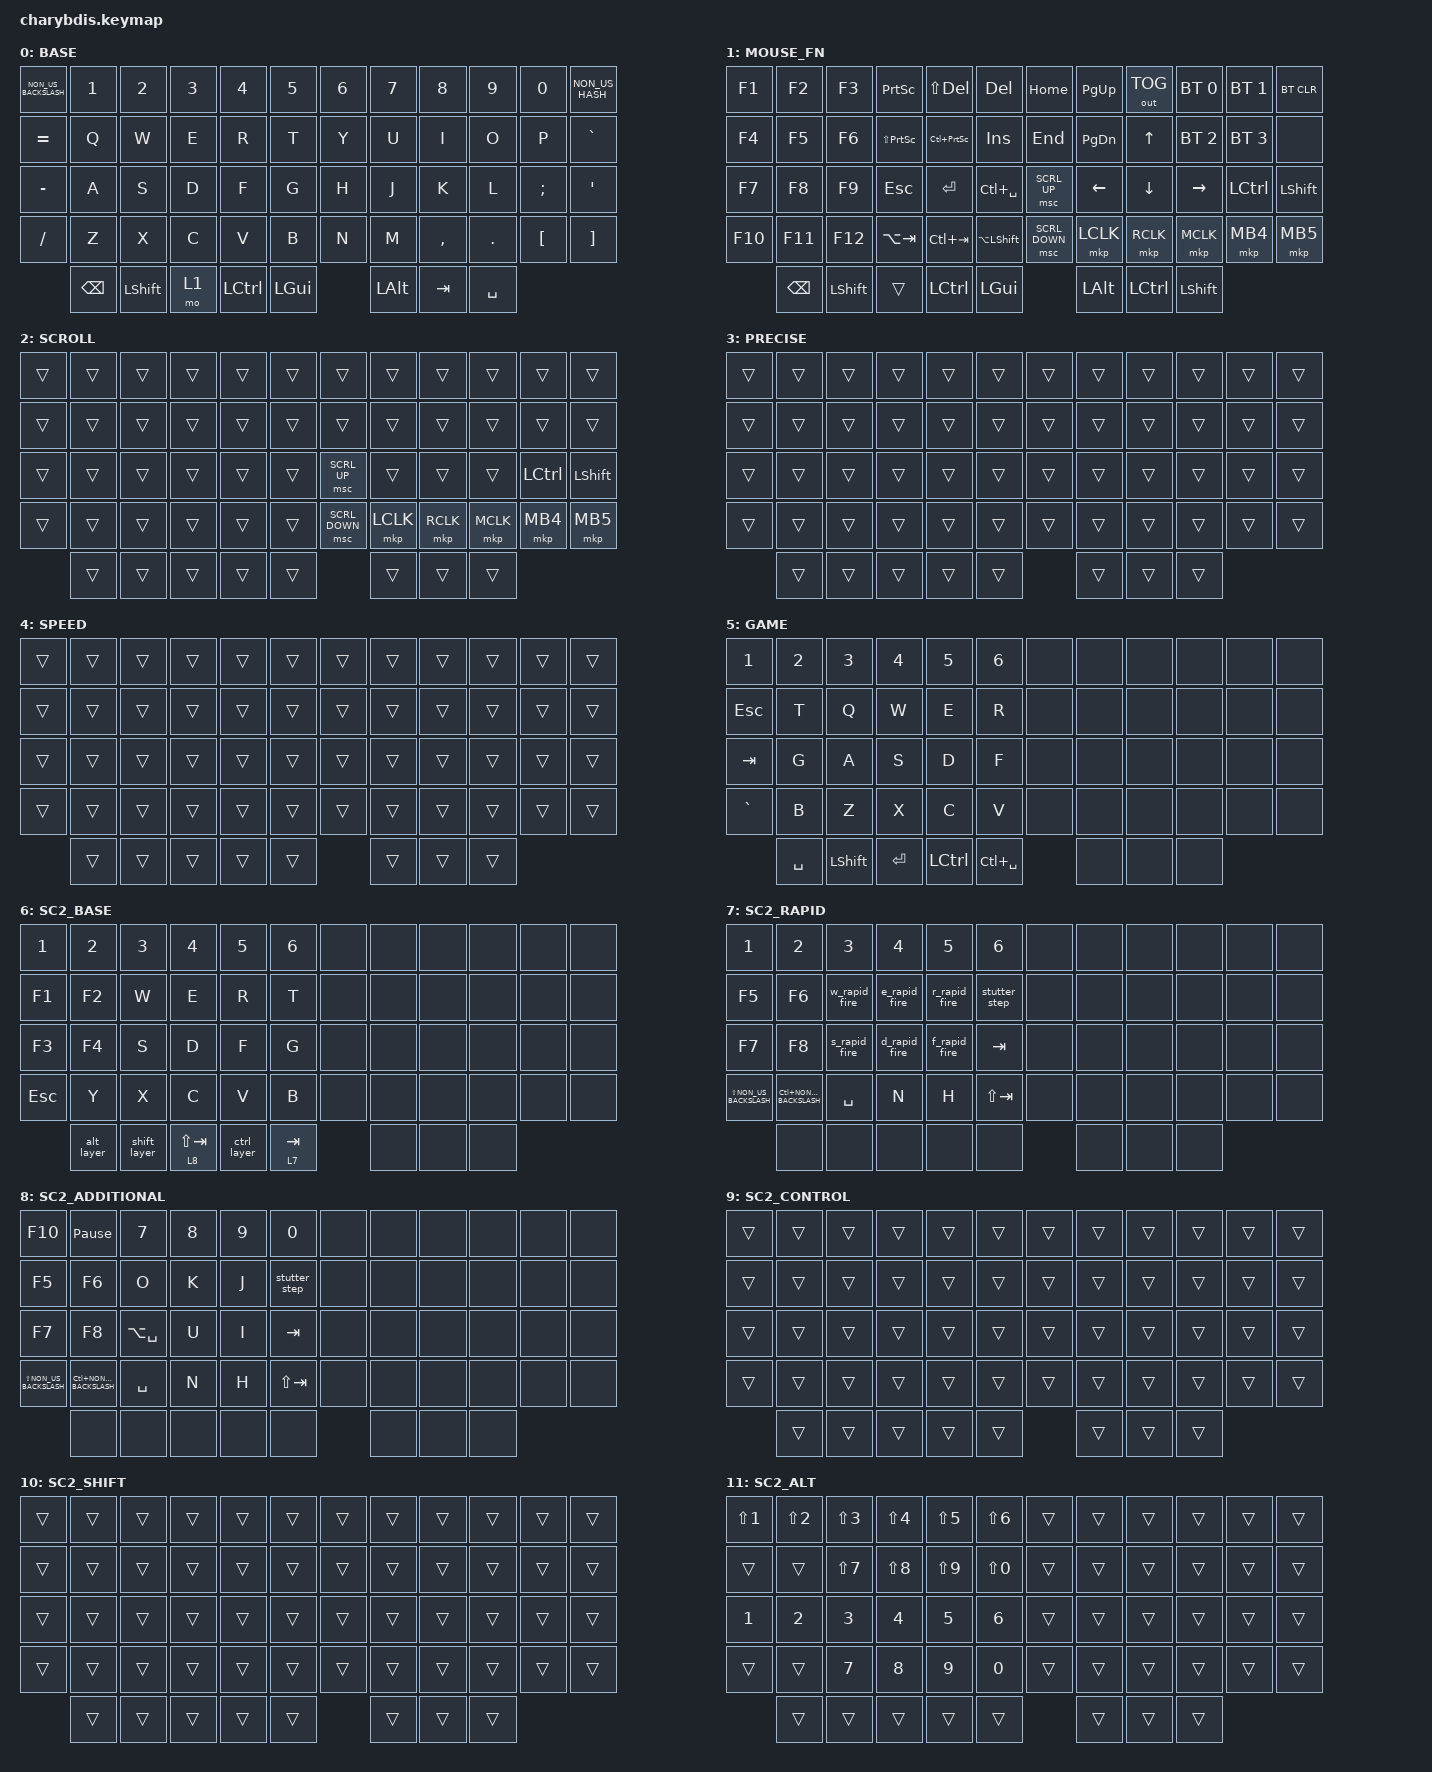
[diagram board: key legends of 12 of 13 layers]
#include <dt-bindings/zmk/mouse.h>
#include <behaviors/mouse_keys.dtsi>
#include <behaviors.dtsi>
#include <dt-bindings/zmk/bt.h>
#include <dt-bindings/zmk/keys.h>
#include <dt-bindings/zmk/outputs.h>
#include <dt-bindings/zmk/pointing.h>
#include "combos.dtsi"
#include "macros.dtsi"

/ {
    chosen { zmk,matrix_transform = &default_transform; };
};

&mt {
    quick-tap-ms = <100>;
    global-quick-tap;
    flavor = "tap-preferred";
    tapping-term-ms = <170>;
};

&lt {
    quick-tap-ms = <100>;
    global-quick-tap;
    flavor = "tap-preferred";
    tapping-term-ms = <170>;
};

/ {
    keymap {
        compatible = "zmk,keymap";

        BASE {
            bindings = <
        &kp NON_US_BACKSLASH  &kp N1      &kp N2      &kp N3      &kp N4      &kp N5        &kp N6      &kp N7      &kp N8      &kp N9      &kp N0      &kp NON_US_HASH
        &kp EQUAL             &kp Q       &kp W       &kp E       &kp R       &kp T         &kp Y       &kp U       &kp I       &kp O       &kp P       &kp GRAVE
        &kp MINUS             &kp A       &kp S       &kp D       &kp F       &kp G         &kp H       &kp J       &kp K       &kp L       &kp SEMI    &kp APOS
        &kp SLASH             &kp Z       &kp X       &kp C       &kp V       &kp B         &kp N       &kp M       &kp COMMA   &kp DOT     &kp LBKT    &kp RBKT
                              &kp BSPC    &kp LSHIFT  &mo 1       &kp LCTRL   &kp LGUI                  &kp LALT    &kp TAB     &kp SPACE
            >;
        };

        MOUSE_FN {
            bindings = <
        &kp F1    &kp F2    &kp F3         &kp PRINTSCREEN   &kp LS(DEL)       &kp DEL           &kp HOME         &kp PG_UP    &out OUT_TOG     &bt BT_SEL 0     &bt BT_SEL 1     &bt BT_CLR
        &kp F4    &kp F5    &kp F6         &kp LS(PSCRN)     &kp LC(PSCRN)     &kp INS           &kp END          &kp PG_DN    &kp UP           &bt BT_SEL 2     &bt BT_SEL 3     &none
        &kp F7    &kp F8    &kp F9         &kp ESC           &kp ENTER         &kp LC(SPACE)     &msc SCRL_UP     &kp LEFT     &kp DOWN         &kp RIGHT        &kp LCTRL        &kp LSHIFT
        &kp F10   &kp F11   &kp F12        &kp LA(TAB)       &kp LC(TAB)       &kp LA(LSHIFT)    &msc SCRL_DOWN   &mkp LCLK    &mkp RCLK        &mkp MCLK        &mkp MB4         &mkp MB5
                  &kp BSPC  &kp LSHIFT     &trans            &kp LCTRL         &kp LGUI                           &kp LALT     &kp LCTRL        &kp LSHIFT
            >;
        };

        SCROLL {
            bindings = <
        &trans  &trans  &trans  &trans  &trans  &trans          &trans        &trans    &trans    &trans    &trans  &trans
        &trans  &trans  &trans  &trans  &trans  &trans          &trans        &trans    &trans    &trans    &trans  &trans
        &trans  &trans  &trans  &trans  &trans  &trans          &msc SCRL_UP  &trans    &trans    &trans    &kp LCTRL &kp LSHIFT
        &trans  &trans  &trans  &trans  &trans  &trans          &msc SCRL_DOWN &mkp LCLK &mkp RCLK &mkp MCLK &mkp MB4 &mkp MB5
                &trans  &trans  &trans  &trans  &trans          &trans &trans &trans
            >;
        };

        PRECISE {
            bindings = <
        &trans  &trans  &trans  &trans  &trans  &trans          &trans        &trans    &trans    &trans    &trans  &trans
        &trans  &trans  &trans  &trans  &trans  &trans          &trans        &trans    &trans    &trans    &trans  &trans
        &trans  &trans  &trans  &trans  &trans  &trans          &trans        &trans    &trans    &trans    &trans  &trans
        &trans  &trans  &trans  &trans  &trans  &trans          &trans        &trans    &trans    &trans    &trans  &trans
                &trans  &trans  &trans  &trans  &trans          &trans &trans &trans
            >;
        };

        SPEED {
            bindings = <
        &trans  &trans  &trans  &trans  &trans  &trans          &trans        &trans    &trans    &trans    &trans  &trans
        &trans  &trans  &trans  &trans  &trans  &trans          &trans        &trans    &trans    &trans    &trans  &trans
        &trans  &trans  &trans  &trans  &trans  &trans          &trans        &trans    &trans    &trans    &trans  &trans
        &trans  &trans  &trans  &trans  &trans  &trans          &trans        &trans    &trans    &trans    &trans  &trans
                &trans  &trans  &trans  &trans  &trans          &trans &trans &trans
            >;
        };

        GAME {
            bindings = <
        &kp N1     &kp N2  &kp N3  &kp N4  &kp N5  &kp N6          &none  &none  &none  &none  &none  &none
        &kp ESC    &kp T   &kp Q   &kp W   &kp E   &kp R           &none  &none  &none  &none  &none  &none
        &kp TAB    &kp G   &kp A   &kp S   &kp D   &kp F           &none  &none  &none  &none  &none  &none
        &kp GRAVE  &kp B   &kp Z   &kp X   &kp C   &kp V           &none  &none  &none  &none  &none  &none
        &kp SPACE  &kp LSHIFT  &kp ENTER   &kp LCTRL  &kp LC(SPACE)       &none  &none  &none
            >;
        };

        /* MY OLD BASIC SC2 LAYER
        SC2_BASIC {
            bindings = <
                &kp N1                    &kp N2      &kp N3      &kp N4      &kp N5      &kp N6          &none         &none       &none       &none       &none       &none
                &kp Y                     &kp Q       &kp W       &kp E       &kp R       &kp T           &none         &none       &none       &none       &none       &none
                &kp NON_US_BACKSLASH      &kp A       &kp S       &kp D       &kp F       &kp G           &none         &none       &none       &none       &none       &none
                &kp ESC                   &kp Z       &kp X       &kp C       &kp V       &kp B           &none         &none       &none       &none       &none       &none
                                          &kp LALT    &kp LSHIFT  &kp TAB     &kp LCTRL   &kp LS(TAB)                   &none       &none       &none
            >;
        };
        */

        SC2_BASE {
            bindings = <
        &kp N1   &kp N2          &kp N3         &kp N4             &kp N5        &kp N6          &none  &none  &none  &none  &none  &none
        &kp F1   &kp F2          &kp W          &kp E              &kp R         &kp T           &none  &none  &none  &none  &none  &none
        &kp F3   &kp F4          &kp S          &kp D              &kp F         &kp G           &none  &none  &none  &none  &none  &none
        &kp ESC  &kp Y           &kp X          &kp C              &kp V         &kp B           &none  &none  &none  &none  &none  &none
                 &alt_layer      &shift_layer   &lt 8 LS(TAB)      &ctrl_layer   &lt 7 TAB          &none  &none  &none
            >;
        };

        SC2_RAPID {
            bindings = <
                &kp N1                      &kp N2                     &kp N3          &kp N4          &kp N5          &kp N6          &none  &none  &none  &none  &none  &none
                &kp F5                      &kp F6                     &w_rapid_fire   &e_rapid_fire   &r_rapid_fire   &stutter_step   &none  &none  &none  &none  &none  &none
                &kp F7                      &kp F8                     &s_rapid_fire   &d_rapid_fire   &f_rapid_fire   &kp TAB         &none  &none  &none  &none  &none  &none
                &kp LS(NON_US_BACKSLASH)    &kp LC(NON_US_BACKSLASH)   &kp SPACE       &kp N           &kp H           &kp LS(TAB)     &none  &none  &none  &none  &none  &none
                         &none      &none           &none           &none           &none                                              &none  &none  &none
            >;
        };

        SC2_ADDITIONAL {
            bindings = <
                &kp F10                     &kp PAUSE_BREAK            &kp N7              &kp N8      &kp N9  &kp N0          &none  &none  &none  &none  &none  &none
                &kp F5                      &kp F6                     &kp O               &kp K       &kp J   &stutter_step   &none  &none  &none  &none  &none  &none
                &kp F7                      &kp F8                     &kp LA(SPACE)       &kp U       &kp I   &kp TAB         &none  &none  &none  &none  &none  &none
                &kp LS(NON_US_BACKSLASH)    &kp LC(NON_US_BACKSLASH)   &kp SPACE           &kp N       &kp H   &kp LS(TAB)     &none  &none  &none  &none  &none  &none
                                            &none                      &none               &none       &none   &none           &none  &none  &none
            >;
        };

        SC2_CONTROL {
            bindings = <
        &trans  &trans  &trans  &trans  &trans  &trans          &trans  &trans  &trans  &trans  &trans  &trans
        &trans  &trans  &trans  &trans  &trans  &trans          &trans  &trans  &trans  &trans  &trans  &trans
        &trans  &trans  &trans  &trans  &trans  &trans          &trans  &trans  &trans  &trans  &trans  &trans
        &trans  &trans  &trans  &trans  &trans  &trans          &trans  &trans  &trans  &trans  &trans  &trans
                &trans  &trans  &trans  &trans  &trans          &trans  &trans  &trans
            >;
        };

        SC2_SHIFT {
            bindings = <
        &trans  &trans  &trans  &trans  &trans  &trans          &trans  &trans  &trans  &trans  &trans  &trans
        &trans  &trans  &trans  &trans  &trans  &trans          &trans  &trans  &trans  &trans  &trans  &trans
        &trans  &trans  &trans  &trans  &trans  &trans          &trans  &trans  &trans  &trans  &trans  &trans
        &trans  &trans  &trans  &trans  &trans  &trans          &trans  &trans  &trans  &trans  &trans  &trans
                &trans  &trans  &trans  &trans  &trans          &trans  &trans  &trans
            >;
        };

        SC2_ALT {
            bindings = <
        &kp LS(N1)  &kp LS(N2)  &kp LS(N3)  &kp LS(N4)  &kp LS(N5)  &kp LS(N6)          &trans  &trans  &trans  &trans  &trans  &trans
        &trans      &trans      &kp LS(N7)  &kp LS(N8)  &kp LS(N9)  &kp LS(N0)          &trans  &trans  &trans  &trans  &trans  &trans
        &kp N1      &kp N2      &kp N3      &kp N4      &kp N5      &kp N6              &trans  &trans  &trans  &trans  &trans  &trans
        &trans      &trans      &kp N7      &kp N8      &kp N9      &kp N0              &trans  &trans  &trans  &trans  &trans  &trans
                    &trans      &trans      &trans      &trans      &trans              &trans  &trans  &trans
            >;
        };

        EMPTY_LAYER {
            bindings = <
        &none  &none  &none  &none  &none  &none          &none  &none  &none  &none  &none  &none
        &none  &none  &none  &none  &none  &none          &none  &none  &none  &none  &none  &none
        &none  &none  &none  &none  &none  &none          &none  &none  &none  &none  &none  &none
        &none  &none  &none  &none  &none  &none          &none  &none  &none  &none  &none  &none
               &none  &none  &none  &none  &none          &none  &none  &none
            >;
        };
    };
};
